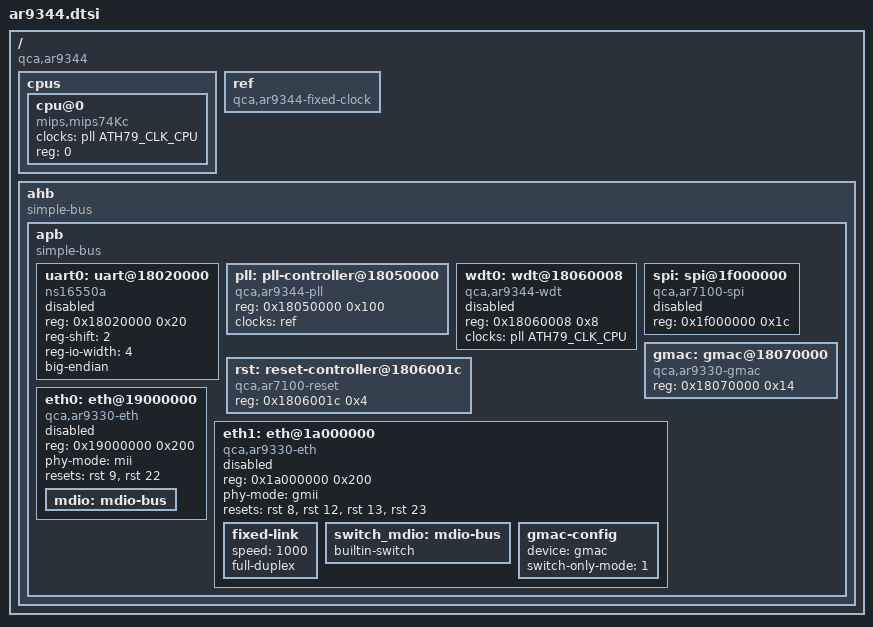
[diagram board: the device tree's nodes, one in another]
#include <dt-bindings/clock/ath79-clk.h>

/ {
	compatible = "qca,ar9344";

	#address-cells = <1>;
	#size-cells = <1>;

	cpus {
		#address-cells = <1>;
		#size-cells = <0>;

		cpu@0 {
			device_type = "cpu";
			compatible = "mips,mips74Kc";
			clocks = <&pll ATH79_CLK_CPU>;
			reg = <0>;
		};
	};

	ref: ref {
		compatible = "qca,ar9344-fixed-clock";
		#clock-cells = <0>;
	};

	ahb {
		compatible = "simple-bus";
		ranges;

		#address-cells = <1>;
		#size-cells = <1>;

		apb {
			compatible = "simple-bus";
			ranges;

			#address-cells = <1>;
			#size-cells = <1>;

			uart0: uart@18020000 {
				compatible = "ns16550a", "qca,ar9344-uart0";
				reg = <0x18020000 0x20>;

				reg-shift = <2>;
				reg-io-width = <4>;
				big-endian;

				status = "disabled";
			};

			pll: pll-controller@18050000 {
				compatible = "qca,ar9344-pll";
				reg = <0x18050000 0x100>;

				clocks = <&ref>;
				clock-names = "ref";

				#clock-cells = <1>;
			};

			wdt0: wdt@18060008 {
				compatible = "qca,ar9344-wdt";
				reg = <0x18060008 0x8>;
				clocks = <&pll ATH79_CLK_CPU>;
				status = "disabled";
			};

			spi: spi@1f000000 {
				compatible = "qca,ar7100-spi", "qca,ar9344-spi";
				reg = <0x1f000000 0x1c>;

				#address-cells = <1>;
				#size-cells = <0>;

				status = "disabled";
			};

			rst: reset-controller@1806001c {
				compatible = "qca,ar7100-reset";
				reg = <0x1806001c 0x4>;

				#reset-cells = <1>;
			};

			gmac: gmac@18070000 {
				compatible = "qca,ar9330-gmac";
				reg = <0x18070000 0x14>;
			};

			eth0: eth@19000000 {
				status = "disabled";

				compatible = "qca,ar9330-eth";
				reg = <0x19000000 0x200>;

				phy-mode = "mii";

				resets = <&rst 9>, <&rst 22>;
				reset-names = "mac", "mdio";

				mdio: mdio-bus {
					status = "okay";
				};
			};

			eth1: eth@1a000000 {
				status = "disabled";

				compatible = "qca,ar9330-eth";
				reg = <0x1a000000 0x200>;

				phy-mode = "gmii";

				resets = <&rst 8>, <&rst 12>, <&rst 13>, <&rst 23>;
				reset-names = "esw", "esw_analog", "mac", "mdio";

				fixed-link {
					speed = <1000>;
					full-duplex;
				};

				switch_mdio: mdio-bus {
					status = "okay";

					builtin-switch;
				};

				gmac-config {
					device = <&gmac>;

					switch-only-mode = <1>;
				};
			};
		};
	};
};
